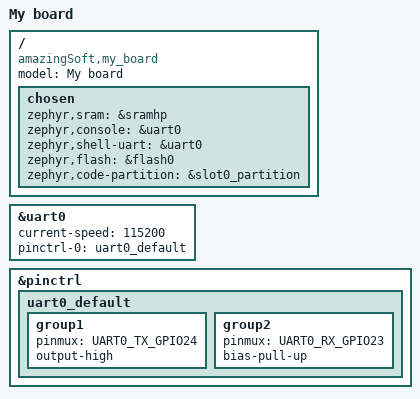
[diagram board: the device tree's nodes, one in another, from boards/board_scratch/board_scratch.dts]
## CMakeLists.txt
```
cmake_minimum_required(VERSION 3.20.0)

set(EXTRA_DTC_OVERLAY_FILE app.overlay)

find_package(Zephyr REQUIRED)
project(my_zephyr_app)

target_sources(app PRIVATE src/main.cpp)
```

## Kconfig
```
# LESSON 4 ---------------------------------------------------------------------
menuconfig LED_HEARTBEAT
    bool "LED heartbeat"
    default y

if LED_HEARTBEAT

    config APP_HEARTBEAT_PERIOD_MS
        int "App heartbeat period time (ms)"
        range 100 2000
        default 500

endif # LED_HEARTBEAT


# LESSON 3 ---------------------------------------------------------------------
# LED Subsystem --->
#     LED blink sleep time (1s (medium)) --->   (250ms,500ms,1s,2s)
#     [ ] Advanced LED settings --->
#         (100) LED brightness (0-100)
#         (500) LED fade duration (ms)
#         Expert settings --->
#             [ ] Enable LED debugging
#             [ ] Custom blink pattern

menuconfig LED_SUBSYSTEM
    bool "LED Subsystem"
    default n

if LED_SUBSYSTEM

    choice
        prompt "LED blink sleep time"
        default BLINK_SLEEP_1000MS

        config BLINK_SLEEP_250MS
            bool "250ms (very fast)"
        config BLINK_SLEEP_500MS
            bool "500ms (Fast)"
        config BLINK_SLEEP_1000MS
            bool "1s (medium)"
        config BLINK_SLEEP_2000MS
            bool "2s (slow)"
    endchoice

    config BLINK_SLEEP_TIME_MS
        int
        default  250 if BLINK_SLEEP_250MS
        default  500 if BLINK_SLEEP_500MS
        default 1000 if BLINK_SLEEP_1000MS
        default 2000 if BLINK_SLEEP_2000MS
        default    0 # not possible, as above 1000ms is default

    menuconfig LED_ADVANCED_SETTINGS
        bool "Advanced LED settings"
        default n

    if LED_ADVANCED_SETTINGS

        config LED_BRIGHTNESS
            int "LED brightness (0-100)"
            range 0 100
            default 100

        config LED_FADE_DURATION_MS
            int "Fade duration (ms)"
            range 0 5000
            default 500

        menu "Expert settings"
            visible if LED_ADVANCED_SETTINGS

            config LED_DEBUG
                bool "Enable LED debugging"
            config LED_PATTERN
                bool "Custom blink pattern"

        endmenu # Expert settings

    endif # LED_ADVANCED_SETTINGS

endif # LED_SUBSYSTEM

source "Kconfig.zephyr"
rsource "drivers/our_driver/Kconfig"
```

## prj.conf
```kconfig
CONFIG_GPIO=y
CONFIG_LOG=y
CONFIG_OUR_DRIVER=y
CONFIG_SHELL=y
#CONFIG_SHELL_MINIMAL=y
```

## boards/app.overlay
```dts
/ {
    leds {
        compatible = "gpio-leds";

        led_4: led_4 {
            gpios = <&gpio0 10 GPIO_ACTIVE_LOW>;
            label = "My Lesson 4 LED";
        };
    };

    our_driver0: our_driver {
        compatible = "our,driver";
        status = "okay";
    };

    aliases {
        app-led = &led_4;
    };
};
```

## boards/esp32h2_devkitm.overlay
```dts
/ {
    leds {
        compatible = "gpio-leds";

        my_led: my_led {
            gpios = <&gpio0 0 GPIO_ACTIVE_LOW>;
            label = "My Custom LED";
        };
    };

    aliases {
        led0 = &my_led;
    };
};
```

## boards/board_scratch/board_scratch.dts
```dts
/dts-v1/;

#include <espressif/esp32h2/esp32h2_mini_h4.dtsi>
#include <espressif/partitions_0x0_default.dtsi>

#include <zephyr/dt-bindings/pinctrl/esp-pinctrl-common.h>
#include <dt-bindings/pinctrl/esp32h2-pinctrl.h>
#include <zephyr/dt-bindings/pinctrl/esp32h2-gpio-sigmap.h>

/ {
	model = "My board";
	compatible = "amazingSoft,my_board";

	chosen {
		zephyr,sram = &sramhp;
		zephyr,console = &uart0;
		zephyr,shell-uart = &uart0;
		zephyr,flash = &flash0;
		zephyr,code-partition = &slot0_partition;
    };
};

&uart0 {
	status = "okay";
	current-speed = <115200>;
	pinctrl-0 = <&uart0_default>;
	pinctrl-names = "default";
};

&pinctrl {
	uart0_default: uart0_default {
		group1 {
			pinmux = <UART0_TX_GPIO24>;
			output-high;
		};

		group2 {
			pinmux = <UART0_RX_GPIO23>;
			bias-pull-up;
		};
	};
};
```

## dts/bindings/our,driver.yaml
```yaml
description: Our simple driver
compatible: "our,driver"
include: base.yaml
```

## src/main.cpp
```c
#include <sys/syslimits.h>
#include <zephyr/drivers/gpio.h>
#include <zephyr/kernel.h>
#include <zephyr/logging/log.h>
#include "zephyr/device.h"
#include "zephyr/drivers/sensor.h"
//#include "zephyr/device.h"

#include "our_driver.h"

#define SLEEP_TIME_MS 5000

LOG_MODULE_REGISTER(main, LOG_LEVEL_INF);

/* MAIN ********************************************************************* */
int main(void)
{
    /* get device */
    const struct device * driver = DEVICE_DT_GET(DT_NODELABEL(our_driver0));
    struct sensor_value val;

    int ret = 0xff;


    printf("Hello World! %s\n", CONFIG_BOARD_TARGET);
    /* MAIN LOOP */
    while (1)
    {
        /*
         *  Disabled for Lesson 07
         *  it would spam in console
         *  and we want to use the Shell
         */
#if 0
        /* turn on  - sleep */
        LOG_INF("turn LED on");
        ret = sensor_sample_fetch(driver);
        LOG_INF("ret: %d\n", ret);
        k_msleep(SLEEP_TIME_MS);

        printInternal(driver);

        /* turn off - sleep */
        LOG_INF("turn LED off");
        ret = sensor_channel_get(driver, SENSOR_CHAN_AMBIENT_TEMP, &val);
        LOG_INF("ret: %d\n", ret);
        k_msleep(SLEEP_TIME_MS);

        if (getTimesOn(driver) >= 10)
        {
            resetTimesOn(driver);
            LOG_INF("resetted times on\n");
        }
#endif

        k_msleep(SLEEP_TIME_MS);
    }

    /* should not be reached */
    return 0;
}
```
